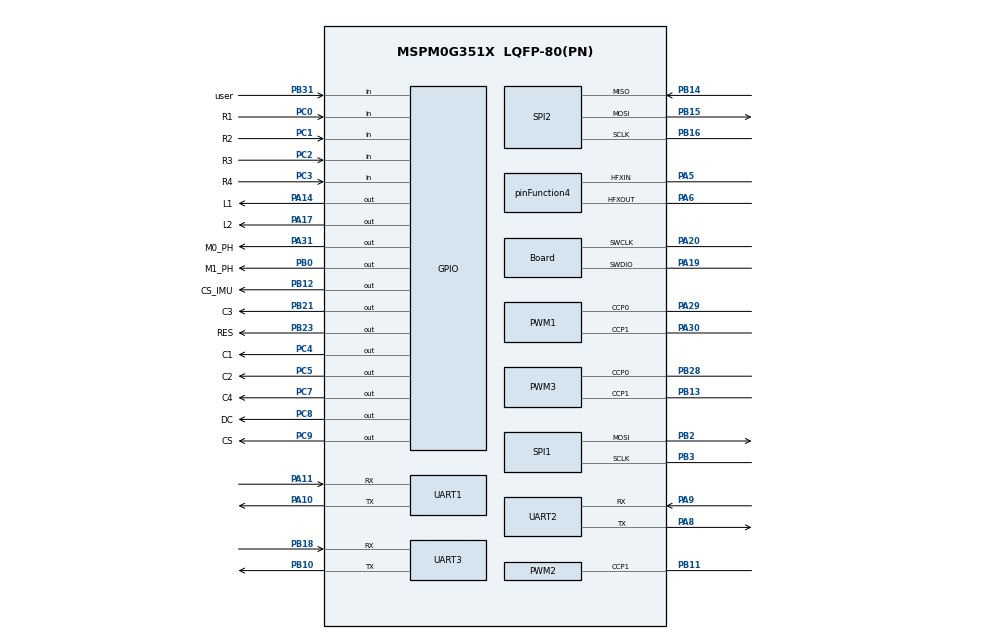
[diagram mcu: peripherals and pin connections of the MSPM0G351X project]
/**
 * @cliArgs --device "MSPM0G351X" --part "Default" --package "LQFP-80(PN)" --product "mspm0_sdk@2.10.00.04"
 * @versions {"tool":"1.27.1+4634"}
 */

/**
 * Import the modules used in this configuration.
 */
const GPIO   = scripting.addModule("/ti/driverlib/GPIO", {}, false);
const GPIO1  = GPIO.addInstance();
const GPIO2  = GPIO.addInstance();
const GPIO3  = GPIO.addInstance();
const GPIO4  = GPIO.addInstance();
const GPIO5  = GPIO.addInstance();
const GPIO6  = GPIO.addInstance();
const PWM    = scripting.addModule("/ti/driverlib/PWM", {}, false);
const PWM1   = PWM.addInstance();
const PWM2   = PWM.addInstance();
const PWM3   = PWM.addInstance();
const SPI    = scripting.addModule("/ti/driverlib/SPI", {}, false);
const SPI1   = SPI.addInstance();
const SPI2   = SPI.addInstance();
const SYSCTL = scripting.addModule("/ti/driverlib/SYSCTL");
const TIMER  = scripting.addModule("/ti/driverlib/TIMER", {}, false);
const TIMER1 = TIMER.addInstance();
const UART   = scripting.addModule("/ti/driverlib/UART", {}, false);
const UART1  = UART.addInstance();
const UART2  = UART.addInstance();
const UART3  = UART.addInstance();

/**
 * Write custom configuration values to the imported modules.
 */
const divider2       = system.clockTree["HFCLK4MFPCLKDIV"];
divider2.divideValue = 10;

const divider9       = system.clockTree["UDIV"];
divider9.divideValue = 2;

const gate7  = system.clockTree["MFCLKGATE"];
gate7.enable = true;

const gate8  = system.clockTree["MFPCLKGATE"];
gate8.enable = true;

const multiplier2         = system.clockTree["PLL_QDIV"];
multiplier2.multiplyValue = 4;

const mux4       = system.clockTree["EXHFMUX"];
mux4.inputSelect = "EXHFMUX_XTAL";

const mux8       = system.clockTree["HSCLKMUX"];
mux8.inputSelect = "HSCLKMUX_SYSPLL0";

const mux10       = system.clockTree["MFPCLKMUX"];
mux10.inputSelect = "MFPCLKMUX_HFCLK";

const mux12       = system.clockTree["SYSPLLMUX"];
mux12.inputSelect = "zSYSPLLMUX_HFCLK";

const pinFunction4                        = system.clockTree["HFXT"];
pinFunction4.inputFreq                    = 40;
pinFunction4.enable                       = true;
pinFunction4.HFXTStartup                  = 100;
pinFunction4.peripheral.$assign           = "SYSCTL";
pinFunction4.peripheral.hfxInPin.$assign  = "PA5";
pinFunction4.peripheral.hfxOutPin.$assign = "PA6";

GPIO1.$name                              = "LED";
GPIO1.associatedPins.create(2);
GPIO1.associatedPins[0].$name            = "L1";
GPIO1.associatedPins[0].internalResistor = "PULL_UP";
GPIO1.associatedPins[0].initialValue     = "SET";
GPIO1.associatedPins[0].pin.$assign      = "PA14";
GPIO1.associatedPins[1].$name            = "L2";
GPIO1.associatedPins[1].internalResistor = "PULL_UP";
GPIO1.associatedPins[1].pin.$assign      = "PA17";

const Board                       = scripting.addModule("/ti/driverlib/Board", {}, false);
Board.peripheral.$assign          = "DEBUGSS";
Board.peripheral.swclkPin.$assign = "PA20";
Board.peripheral.swdioPin.$assign = "PA19";

GPIO2.$name                              = "key";
GPIO2.associatedPins[0].$name            = "user";
GPIO2.associatedPins[0].direction        = "INPUT";
GPIO2.associatedPins[0].interruptEn      = true;
GPIO2.associatedPins[0].polarity         = "FALL";
GPIO2.associatedPins[0].internalResistor = "PULL_UP";
GPIO2.associatedPins[0].pin.$assign      = "PB31";

GPIO3.$name                              = "OLED";
GPIO3.associatedPins.create(3);
GPIO3.associatedPins[0].$name            = "RES";
GPIO3.associatedPins[0].pin.$assign      = "PB23";
GPIO3.associatedPins[1].$name            = "DC";
GPIO3.associatedPins[1].pin.$assign      = "PC8";
GPIO3.associatedPins[2].$name            = "CS";
GPIO3.associatedPins[2].internalResistor = "PULL_UP";
GPIO3.associatedPins[2].pin.$assign      = "PC9";

GPIO4.$name                              = "IMU";
GPIO4.associatedPins[0].$name            = "CS_IMU";
GPIO4.associatedPins[0].internalResistor = "PULL_UP";
GPIO4.associatedPins[0].pin.$assign      = "PB12";

GPIO5.$name                         = "Motor_DIR";
GPIO5.associatedPins.create(2);
GPIO5.associatedPins[0].$name       = "M0_PH";
GPIO5.associatedPins[0].pin.$assign = "PA31";
GPIO5.associatedPins[1].$name       = "M1_PH";
GPIO5.associatedPins[1].pin.$assign = "PB0";

GPIO6.$name                              = "MatrixKeypad";
GPIO6.associatedPins.create(8);
GPIO6.associatedPins[0].$name            = "R1";
GPIO6.associatedPins[0].direction        = "INPUT";
GPIO6.associatedPins[0].internalResistor = "PULL_UP";
GPIO6.associatedPins[0].pin.$assign      = "PC0";
GPIO6.associatedPins[1].$name            = "R2";
GPIO6.associatedPins[1].direction        = "INPUT";
GPIO6.associatedPins[1].internalResistor = "PULL_UP";
GPIO6.associatedPins[1].pin.$assign      = "PC1";
GPIO6.associatedPins[2].$name            = "R3";
GPIO6.associatedPins[2].direction        = "INPUT";
GPIO6.associatedPins[2].internalResistor = "PULL_UP";
GPIO6.associatedPins[2].pin.$assign      = "PC2";
GPIO6.associatedPins[3].$name            = "R4";
GPIO6.associatedPins[3].direction        = "INPUT";
GPIO6.associatedPins[3].internalResistor = "PULL_UP";
GPIO6.associatedPins[3].pin.$assign      = "PC3";
GPIO6.associatedPins[4].$name            = "C1";
GPIO6.associatedPins[4].pin.$assign      = "PC4";
GPIO6.associatedPins[5].$name            = "C2";
GPIO6.associatedPins[5].pin.$assign      = "PC5";
GPIO6.associatedPins[6].$name            = "C3";
GPIO6.associatedPins[6].pin.$assign      = "PB21";
GPIO6.associatedPins[7].$name            = "C4";
GPIO6.associatedPins[7].pin.$assign      = "PC7";

PWM1.$name                              = "TimerG6_PWM";
PWM1.interrupts                         = ["LOAD_EVENT"];
PWM1.timerCount                         = 100;
PWM1.timerStartTimer                    = true;
PWM1.peripheral.$assign                 = "TIMG6";
PWM1.peripheral.ccp0Pin.$assign         = "PA29";
PWM1.peripheral.ccp1Pin.$assign         = "PA30";
PWM1.PWM_CHANNEL_0.$name                = "ti_driverlib_pwm_PWMTimerCC0";
PWM1.PWM_CHANNEL_0.dutyCycle            = 50;
PWM1.PWM_CHANNEL_1.$name                = "ti_driverlib_pwm_PWMTimerCC1";
PWM1.PWM_CHANNEL_1.dutyCycle            = 5;
PWM1.ccp0PinConfig.direction            = scripting.forceWrite("OUTPUT");
PWM1.ccp0PinConfig.hideOutputInversion  = scripting.forceWrite(false);
PWM1.ccp0PinConfig.onlyInternalResistor = scripting.forceWrite(false);
PWM1.ccp0PinConfig.passedPeripheralType = scripting.forceWrite("Digital");
PWM1.ccp0PinConfig.$name                = "ti_driverlib_gpio_GPIOPinGeneric2";
PWM1.ccp1PinConfig.direction            = scripting.forceWrite("OUTPUT");
PWM1.ccp1PinConfig.hideOutputInversion  = scripting.forceWrite(false);
PWM1.ccp1PinConfig.onlyInternalResistor = scripting.forceWrite(false);
PWM1.ccp1PinConfig.passedPeripheralType = scripting.forceWrite("Digital");
PWM1.ccp1PinConfig.$name                = "ti_driverlib_gpio_GPIOPinGeneric3";

PWM2.$name                              = "TIMG0_Buzzer";
PWM2.timerCount                         = 20000;
PWM2.timerStartTimer                    = true;
PWM2.ccIndex                            = [1];
PWM2.ccp1PinConfig.direction            = scripting.forceWrite("OUTPUT");
PWM2.ccp1PinConfig.hideOutputInversion  = scripting.forceWrite(false);
PWM2.ccp1PinConfig.onlyInternalResistor = scripting.forceWrite(false);
PWM2.ccp1PinConfig.passedPeripheralType = scripting.forceWrite("Digital");
PWM2.ccp1PinConfig.$name                = "ti_driverlib_gpio_GPIOPinGeneric13";
PWM2.peripheral.$assign                 = "TIMG0";
PWM2.peripheral.ccp1Pin.$assign         = "PB11";
PWM2.PWM_CHANNEL_1.$name                = "ti_driverlib_pwm_PWMTimerCC2";

PWM3.$name                              = "TIMG14_Motor";
PWM3.timerCount                         = 4000;
PWM3.timerStartTimer                    = true;
PWM3.peripheral.$assign                 = "TIMG14";
PWM3.peripheral.ccp0Pin.$assign         = "PB28";
PWM3.peripheral.ccp1Pin.$assign         = "PB13";
PWM3.PWM_CHANNEL_0.$name                = "ti_driverlib_pwm_PWMTimerCC0_3";
PWM3.PWM_CHANNEL_0.dutyCycle            = 50;
PWM3.PWM_CHANNEL_1.$name                = "ti_driverlib_pwm_PWMTimerCC1_3";
PWM3.PWM_CHANNEL_1.dutyCycle            = 50;
PWM3.ccp0PinConfig.direction            = scripting.forceWrite("OUTPUT");
PWM3.ccp0PinConfig.hideOutputInversion  = scripting.forceWrite(false);
PWM3.ccp0PinConfig.onlyInternalResistor = scripting.forceWrite(false);
PWM3.ccp0PinConfig.passedPeripheralType = scripting.forceWrite("Digital");
PWM3.ccp0PinConfig.$name                = "ti_driverlib_gpio_GPIOPinGeneric14";
PWM3.ccp1PinConfig.direction            = scripting.forceWrite("OUTPUT");
PWM3.ccp1PinConfig.hideOutputInversion  = scripting.forceWrite(false);
PWM3.ccp1PinConfig.onlyInternalResistor = scripting.forceWrite(false);
PWM3.ccp1PinConfig.passedPeripheralType = scripting.forceWrite("Digital");
PWM3.ccp1PinConfig.$name                = "ti_driverlib_gpio_GPIOPinGeneric15";

SPI1.$name                      = "SPI_0";
SPI1.frameFormat                = "MOTO3";
SPI1.direction                  = "PICO";
SPI1.polarity                   = "1";
SPI1.phase                      = "1";
SPI1.targetBitRate              = 20000000;
SPI1.sclkPinConfig.$name        = "ti_driverlib_gpio_GPIOPinGeneric4";
SPI1.mosiPinConfig.$name        = "ti_driverlib_gpio_GPIOPinGeneric5";
SPI1.peripheral.sclkPin.$assign = "PB3";
SPI1.peripheral.mosiPin.$assign = "PB2";

SPI2.$name                      = "SPI_1";
SPI2.frameFormat                = "MOTO3";
SPI2.polarity                   = "1";
SPI2.phase                      = "1";
SPI2.targetBitRate              = 200000;
SPI2.sclkPinConfig.$name        = "ti_driverlib_gpio_GPIOPinGeneric6";
SPI2.mosiPinConfig.$name        = "ti_driverlib_gpio_GPIOPinGeneric7";
SPI2.misoPinConfig.$name        = "ti_driverlib_gpio_GPIOPinGeneric8";
SPI2.peripheral.$assign         = "SPI1";
SPI2.peripheral.sclkPin.$assign = "PB16";
SPI2.peripheral.mosiPin.$assign = "PB15";
SPI2.peripheral.misoPin.$assign = "PB14";

SYSCTL.forceDefaultClkConfig = true;
SYSCTL.clockTreeEn           = true;

TIMER1.timerStartTimer    = true;
TIMER1.interrupts         = ["LOAD"];
TIMER1.timerMode          = "PERIODIC_UP";
TIMER1.timerClkDiv        = 8;
TIMER1.timerClkPrescale   = 100;
TIMER1.$name              = "TimerA1";
TIMER1.timerPeriod        = "100us";
TIMER1.peripheral.$assign = "TIMA1";

UART1.$name                    = "UART_0";
UART1.enabledInterrupts        = ["RX"];
UART1.uartClkDiv               = "2";
UART1.targetBaudRate           = 115200;
UART1.peripheral.$assign       = "UART0";
UART1.peripheral.rxPin.$assign = "PA11";
UART1.peripheral.txPin.$assign = "PA10";
UART1.txPinConfig.$name        = "ti_driverlib_gpio_GPIOPinGeneric0";
UART1.rxPinConfig.$name        = "ti_driverlib_gpio_GPIOPinGeneric1";

UART2.$name                    = "UART_1";
UART2.enabledInterrupts        = ["RX"];
UART2.uartClkDiv               = "2";
UART2.targetBaudRate           = 115200;
UART2.peripheral.$assign       = "UART1";
UART2.peripheral.rxPin.$assign = "PA9";
UART2.peripheral.txPin.$assign = "PA8";
UART2.txPinConfig.$name        = "ti_driverlib_gpio_GPIOPinGeneric9";
UART2.rxPinConfig.$name        = "ti_driverlib_gpio_GPIOPinGeneric10";

UART3.$name                            = "UART_4";
UART3.uartClkDiv                       = "2";
UART3.targetBaudRate                   = 115200;
UART3.peripheral.$assign               = "UART4";
UART3.peripheral.rxPin.$assign         = "PB18";
UART3.peripheral.txPin.$assign         = "PB10";
UART3.txPinConfig.direction            = scripting.forceWrite("OUTPUT");
UART3.txPinConfig.hideOutputInversion  = scripting.forceWrite(false);
UART3.txPinConfig.onlyInternalResistor = scripting.forceWrite(false);
UART3.txPinConfig.passedPeripheralType = scripting.forceWrite("Digital");
UART3.txPinConfig.$name                = "ti_driverlib_gpio_GPIOPinGeneric11";
UART3.rxPinConfig.hideOutputInversion  = scripting.forceWrite(false);
UART3.rxPinConfig.onlyInternalResistor = scripting.forceWrite(false);
UART3.rxPinConfig.passedPeripheralType = scripting.forceWrite("Digital");
UART3.rxPinConfig.$name                = "ti_driverlib_gpio_GPIOPinGeneric12";

const ProjectConfig              = scripting.addModule("/ti/project_config/ProjectConfig", {}, false);
ProjectConfig.migrationCondition = true;

/**
 * Pinmux solution for unlocked pins/peripherals. This ensures that minor changes to the automatic solver in a future
 * version of the tool will not impact the pinmux you originally saw.  These lines can be completely deleted in order to
 * re-solve from scratch.
 */
SPI1.peripheral.$suggestSolution = "SPI0";
